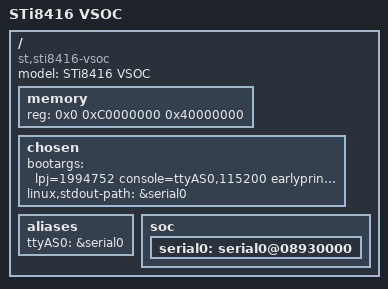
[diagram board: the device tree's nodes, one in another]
/*
 * Copyright (C) 2014 STMicroelectronics (R&D) Limited.
 * Author: Nunzio Raciti <nunzio.raciti@st.com>
 * Author: Madianga M'boumba Cedric <cedric.madianga@st.com>
 *
 * This program is free software; you can redistribute it and/or modify
 * it under the terms of the GNU General Public License version 2 as
 * published by the Free Software Foundation.
 */
/dts-v1/;

#include "sti8416.dtsi"

/ {
	model = "STi8416 VSOC";
	compatible = "st,sti8416-vsoc", "st,sti8416";

	memory {
		device_type = "memory";
		reg = <0x0 0xC0000000 0x40000000>;
	};

	chosen {
		bootargs = "lpj=1994752 console=ttyAS0,115200 earlyprintk=st-asc,0x08930000";
		linux,stdout-path = &serial0;
	};

	aliases {
		ttyAS0 = &serial0;
	};

	soc {
		serial0: serial0@08930000 {
			status = "okay";
		};
	};
};
